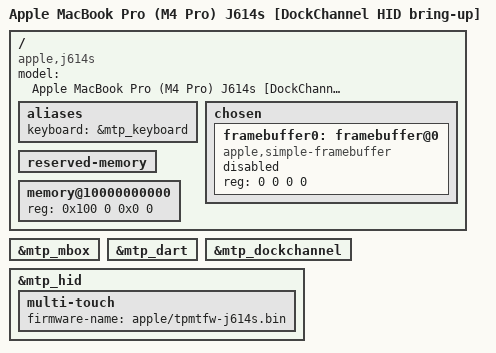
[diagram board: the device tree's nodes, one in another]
// SPDX-License-Identifier: GPL-2.0+ OR MIT
/*
 * Apple MacBook Pro J614s keyboard bring-up variant.
 *
 * This keeps the proven framebuffer console decoupled from PMGR and enables
 * only the ADT-derived MTP/DockChannel path needed by the internal HID devices.
 */
/dts-v1/;

#include "t6040.dtsi"

/ {
	compatible = "apple,j614s", "apple,t6040", "apple,arm-platform";
	model = "Apple MacBook Pro (M4 Pro) J614s [DockChannel HID bring-up]";

	aliases {
		keyboard = &mtp_keyboard;
	};

	chosen {
		#address-cells = <2>;
		#size-cells = <2>;
		ranges;

		framebuffer0: framebuffer@0 {
			compatible = "apple,simple-framebuffer", "simple-framebuffer";
			reg = <0 0 0 0>; /* To be filled by loader */
			status = "disabled";
		};
	};

	reserved-memory {
		#address-cells = <2>;
		#size-cells = <2>;
		ranges;
	};

	memory@10000000000 {
		device_type = "memory";
		reg = <0x100 0 0x0 0>; /* To be filled by loader */
	};
};

&mtp_mbox {
	status = "okay";
};

&mtp_dart {
	status = "okay";
};

&mtp_dockchannel {
	status = "okay";
};

&mtp_hid {
	status = "okay";

	multi-touch {
		firmware-name = "apple/tpmtfw-j614s.bin";
	};
};
